# MM32F3270 register map
File version: 3.01
CPU: CM3 r2p1, selectable endian, MPU, no FPU, 3 interrupt priority bits
Registers are 32-bit, read-write, reset 0x0 unless marked. A register's access mark holds for its fields unless they carry their own. Offsets are from the block's base; [hi:lo] are bit positions.

## SPI1 — Serial peripheral interface
Base 0x40013000
Same registers: SPI2 0x40003800, SPI3 0x40003C00
0x00 TDR — Transmit data register
  [31:0] TXREG
0x04 RDR ro — Receive data register
  [31:0] RXREG
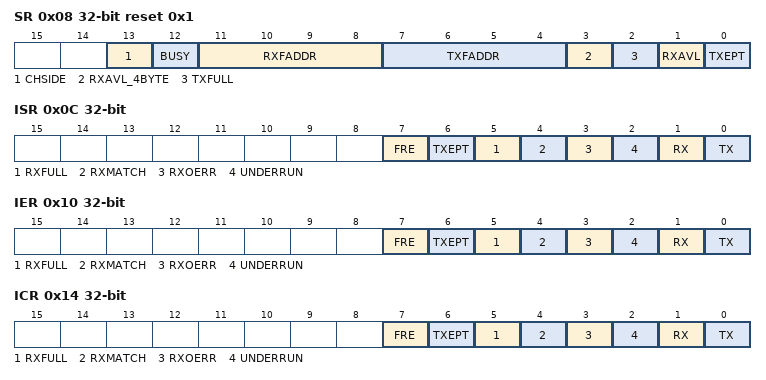
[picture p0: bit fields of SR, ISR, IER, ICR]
0x08 SR ro reset 0x1 — Current status register
  [13] CHSIDE — Is the channel currently being transmitted is the left channel or the right channel
  [12] BUSY — Is there any data currently being transferred
  [11:8] RXFADDR — Transmit FIFO address
  [7:4] TXFADDR — Receive FIFO address
  [3] RXAVL_4BYTE — Receive available 4 byte data message
  [2] TXFULL — Transmitter FIFO full status bit
  [1] RXAVL — Receive available byte data message
  [0] TXEPT — Transmitter empty bit
0x0C ISR ro — Interrupt status register
  [7] FRE — I2S frame transmission error flag bit (only valid in slave mode)
  [6] TXEPT — Transmitter empty interrupt flag bit
  [5] RXFULL — RX FIFO full interrupt flag bit
  [4] RXMATCH — Receive data match the RDNR number
  [3] RXOERR — Receive overrun error interrupt flag bit
  [2] UNDERRUN — SPI underrun interrupt flag bit
  [1] RX — Receive data available interrupt flag bit
  [0] TX — Transmit FIFO avialable interrupt flag bit
0x10 IER — Interrupt enable register
  [7] FRE — I2S frame transmission error interrupt enable bit
  [6] TXEPT — Transmit empty interrupt enable bit
  [5] RXFULL — Receive FIFO full interrupt enable bit
  [4] RXMATCH — Receive data complete interrupt enable bit
  [3] RXOERR — Overrun error interrupt enable bit
  [2] UNDERRUN — Transmitter underrun interrupt enable bit(SPI slave mode only)
  [1] RX — Receive FIFO interrupt enable bit
  [0] TX — Transmit FIFO empty interrupt enable bit
0x14 ICR — Interrupt clear register
  [7] FRE — I2S frame transmission error interrupt clear
  [6] TXEPT — Transmitter empty interrupt clear bit
  [5] RXFULL — Receiver buffer full interrupt clear bit
  [4] RXMATCH — Receive completed interrupt clear bit
  [3] RXOERR — Overrun error interrupt clear bit
  [2] UNDERRUN — Transmitter underrun interrupt clear bit(SPI slave mode only)
  [1] RX — Receive interrupt clear bit
  [0] TX — Transmitter FIFO empty interrupt clear bit
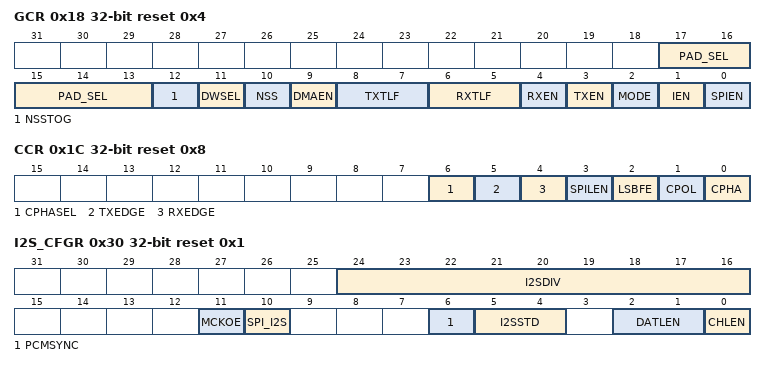
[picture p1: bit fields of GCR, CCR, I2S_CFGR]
0x18 GCR reset 0x4 — Global control register
  [17:13] PAD_SEL — Bus mapping transformation.
  [12] NSSTOG — NSS selection signal is automatically flipped
  [11] DWSEL — Valid byte or double-word data select signal
  [10] NSS — NSS select signal that from software and hardware
  [9] DMAEN — DMA access mode enable
  [8:7] TXTLF — TX FIFO trigger level bit
  [6:5] RXTLF — RX FIFO trigger level bit
  [4] RXEN — Receive enable bit
  [3] TXEN — Transmit enable bit
  [2] MODE — Master mode bit
  [1] IEN — SPI interrupt enable bit
  [0] SPIEN — SPI select bit
0x1C CCR reset 0x8 — Current control register
  [6] CPHASEL — CPHA polarity select
  [5] TXEDGE — Transmit data edge select
  [4] RXEDGE — Receive data edge select
  [3] SPILEN — SPI character length bit
  [2] LSBFE — LSI first enable bit
  [1] CPOL — Clock polarity select bit
  [0] CPHA — Clock phase select bit
0x20 BRR reset 0x2 — Baud rate generation register
  [15:0] DIVF — SPI baud rate control register for baud rate
0x24 RDNR reset 0x1 — Receive data count register
  [15:0] RDN — The register is used to hold a count of to be received bytes in next receive process
0x28 NSSR 16-bit reset 0xFF — Slave chip select register
  [7:0] NSS — Chip select output signal in Master mode
0x2C ECR reset 0x8 — Extent data control register
  [4:0] EXTLEN — Control SPI data length
0x30 I2S_CFGR reset 0x1 — I2S Configuration register
  [24:16] I2SDIV — Frequency division coefficient of I2S prescaler, configuration is valid in main mode
  [11] MCKOE — I2S master clock output enable
  [10] SPI_I2S — SPI/I2S module function selection
  [6] PCMSYNC — PCM frame synchronization mode
  [5:4] I2SSTD — I2S standard selection
  [2:1] DATLEN — Audio data width
  [0] CHLEN — Channel length
